# STM32U345xx register map
File version: 1.0
Registers are 32-bit, read-write, reset 0x0 unless marked. A register's access mark holds for its fields unless they carry their own. Offsets are from the block's base; [hi:lo] are bit positions; {n}, {i} and the like mark numbered series; 'fields as' and 'values as' point back to an identical list.

## TAMP — Tamper and backup registers
Base 0x40007C00
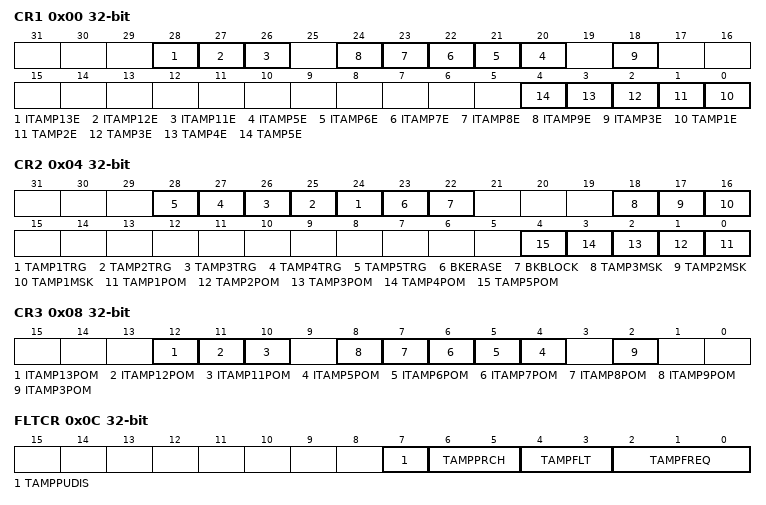
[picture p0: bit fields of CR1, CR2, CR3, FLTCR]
0x00 CR1 — TAMP configuration register 1
  [28] ITAMP13E, [27] ITAMP12E, [26] ITAMP11E, [n+15] ITAMP{n}E (n=5..9), [18] ITAMP3E, [n-1] TAMP{n}E (n=1..5)
0x04 CR2 — TAMP configuration register 2
  [n+23] TAMP{n}TRG (n=1..5), [23] BKERASE, [22] BKBLOCK, [18] TAMP3MSK, [17] TAMP2MSK, [16] TAMP1MSK, [n-1] TAMP{n}POM (n=1..5)
0x08 CR3 — TAMP configuration register 3
  [12] ITAMP13POM, [11] ITAMP12POM, [10] ITAMP11POM, [n-1] ITAMP{n}POM (n=5..9), [2] ITAMP3POM
0x0C FLTCR — TAMP filter control register
  [7] TAMPPUDIS
  [6:5] TAMPPRCH
    0=DURATION_1RTCCLK (Tamper pins are pre-charged before sampling during 1 RTCCLK cycle); 1=DURATION_2RTCCLK (Tamper pins are pre-charged before sampling during 2 RTCCLK cycles); 2=DURATION_4RTCCLK (Tamper pins are pre-charged before sampling during 4 RTCCLK cycles); 3=DURATION_8RTCCLK (Tamper pins are pre-charged before sampling during 8 RTCCLK cycles)
  [4:3] TAMPFLT
    0=DISABLE (Tamper filter is disabled); 1=FILTER_2SAMPLE (Tamper is activated after 2 consecutive samples at the active level); 2=FILTER_4SAMPLE (Tamper is activated after 4 consecutive samples at the active level); 3=FILTER_8SAMPLE (Tamper is activated after 8 consecutive samples at the active level)
  [2:0] TAMPFREQ
    0=SAMPLFREQDIV_32768 (Each of the tamper inputs are sampled with a frequency = RTCCLK / 32768); 1=SAMPLFREQDIV_16384 (Each of the tamper inputs are sampled with a frequency = RTCCLK / 16384); 2=SAMPLFREQDIV_8192 (Each of the tamper inputs are sampled with a frequency = RTCCLK / 8192); 3=SAMPLFREQDIV_4096 (Each of the tamper inputs are sampled with a frequency = RTCCLK / 4096); 4=SAMPLFREQDIV_2048 (Each of the tamper inputs are sampled with a frequency = RTCCLK / 2048); 5=SAMPLFREQDIV_1024 (Each of the tamper inputs are sampled with a frequency = RTCCLK / 1024); 6=SAMPLFREQDIV_512 (Each of the tamper inputs are sampled with a frequency = RTCCLK / 512); 7=SAMPLFREQDIV_256 (Each of the tamper inputs are sampled with a frequency = RTCCLK / 256)
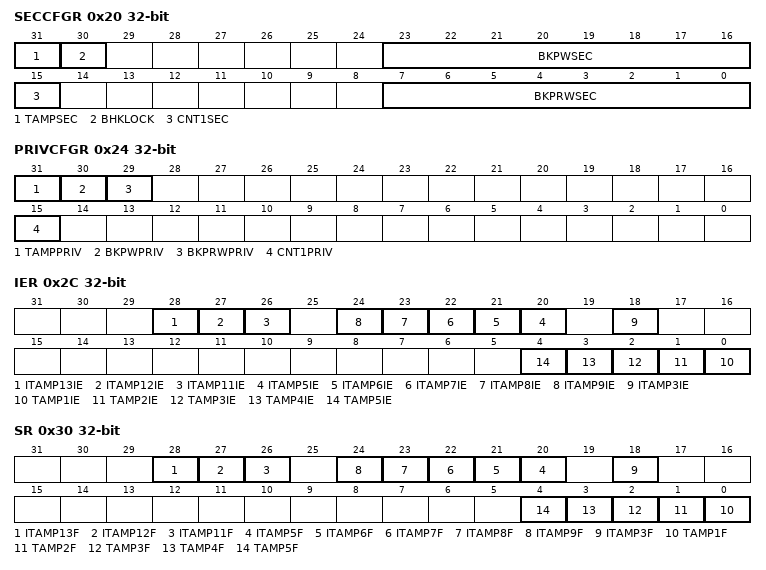
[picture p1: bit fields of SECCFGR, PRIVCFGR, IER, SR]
0x20 SECCFGR — TAMP secure mode control register
  [31] TAMPSEC
    1=YES (TAMP full secure); 0=NO (TAMP is not secure)
  [30] BHKLOCK
  [23:16] BKPWSEC
  [15] CNT1SEC
  [7:0] BKPRWSEC
0x24 PRIVCFGR — TAMP privilege mode control register
  [31] TAMPPRIV
    1=YES (TAMP full privilege); 0=NO (TAMP is not privilege)
  [30] BKPWPRIV
  [29] BKPRWPRIV
  [15] CNT1PRIV
0x2C IER — TAMP interrupt enable register
  [28] ITAMP13IE, [27] ITAMP12IE, [26] ITAMP11IE, [n+15] ITAMP{n}IE (n=5..9), [18] ITAMP3IE, [n-1] TAMP{n}IE (n=1..5)
0x30 SR — TAMP status register
  [28] ITAMP13F, [27] ITAMP12F, [26] ITAMP11F, [n+15] ITAMP{n}F (n=5..9), [18] ITAMP3F, [n-1] TAMP{n}F (n=1..5)
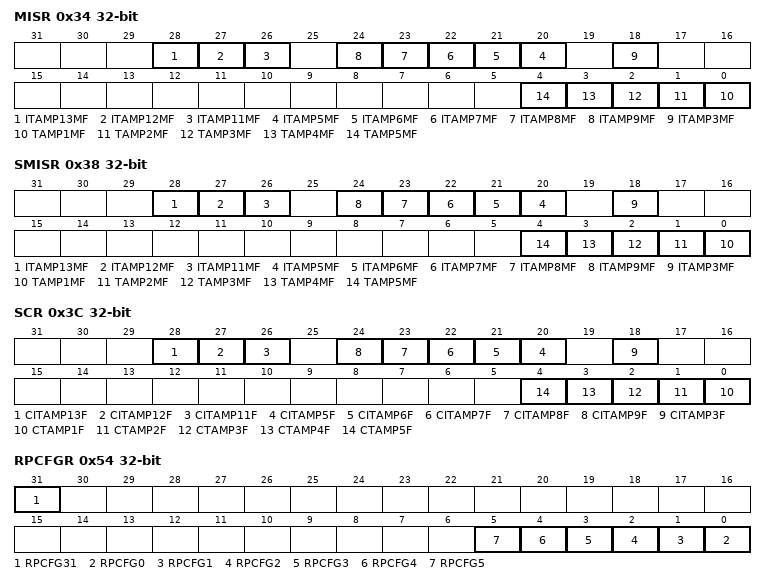
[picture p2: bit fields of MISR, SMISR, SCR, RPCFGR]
0x34 MISR — TAMP masked interrupt status register
  [28] ITAMP13MF, [27] ITAMP12MF, [26] ITAMP11MF, [n+15] ITAMP{n}MF (n=5..9), [18] ITAMP3MF, [n-1] TAMP{n}MF (n=1..5)
0x38 SMISR — TAMP secure masked interrupt status register
  fields as MISR
0x3C SCR — TAMP status clear register
  [28] CITAMP13F, [27] CITAMP12F, [26] CITAMP11F, [n+15] CITAMP{n}F (n=5..9), [18] CITAMP3F, [n-1] CTAMP{n}F (n=1..5)
0x40 COUNT1R — TAMP monotonic counter register
  [31:0] COUNT
0x54 RPCFGR — TAMP resources protection configuration register
  [31] RPCFG31, [n] RPCFG{n} (n=0..5)
{0x100+4i} BKP{i}R (i=0..31) — TAMP backup register {i}

## FDCAN_CONFIG — FD Controller Area Network Configuration
Base 0x4000A500
0x00 CKDIV — FDCAN clock divider register
  [3:0] PDIV — Input Clock Divider
0x204 OPTR — FDCAN option register
0x2F0 HWCFG — FDCAN hardware configuration register
0x2F4 VERR — FDCAN IP version register
0x2F8 IPIDR — FDCAN IP ID register
0x2FC SIDR — FDCAN size ID register

## USB_DRD_FS — Universal Serial Bus Full Speed Dual Role Device
Base 0x40016000
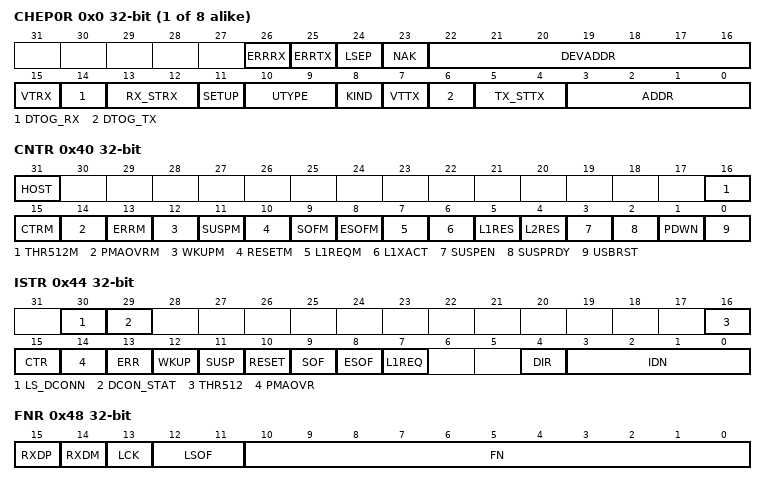
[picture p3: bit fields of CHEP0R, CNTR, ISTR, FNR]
{0x0+4i} CHEP{i}R (i=0..7) — USB Channel/Endpoint {i} register
  [26] ERRRX — Receive error
  [25] ERRTX — Transmit error
  [24] LSEP — Low Speed Endpoint (host with Hub Only)
  [23] NAK — Previous NAK detected
  [22:16] DEVADDR
  [15] VTRX — USB valid transaction received Mask
  [14] DTOG_RX — Data Toggle, for reception transfers Mask
  [13:12] RX_STRX — Status bits, for reception transfers Mask
  [11] SETUP — Setup transaction completed Mask
  [10:9] UTYPE — USB type of transaction Mask
  [8] KIND — EndPoint KIND Mask
  [7] VTTX — Valid USB transaction transmitted Mask
  [6] DTOG_TX — Data Toggle, for transmission transfers Mask
  [5:4] TX_STTX — Status bits, for transmission transfers Mask
  [3:0] ADDR — Endpoint address Mask
0x40 CNTR — Control register
  [31] HOST — Host Mode
  [16] THR512M — 512byte Threshold interrupt mask
  [15] CTRM — Correct Transfer Mask
  [14] PMAOVRM — DMA OVeR/underrun Mask
  [13] ERRM — ERRor Mask
  [12] WKUPM — WaKe UP Mask
  [11] SUSPM — SUSPend Mask
  [10] RESETM — RESET Mask
  [9] SOFM — Start Of Frame Mask
  [8] ESOFM — Expected Start Of Frame Mask
  [7] L1REQM — LPM L1 state request interrupt Mask
  [6] L1XACT — Host LPM L1 transaction request Mask
  [5] L1RES — LPM L1 Resume request/ Remote Wakeup Mask
  [4] L2RES — L2 Remote Wakeup / Resume driver Mask
  [3] SUSPEN — Suspend state enable Mask
  [2] SUSPRDY — Suspend state effective Mask
  [1] PDWN — Power DoWN Mask
  [0] USBRST — USB Reset Mask
0x44 ISTR — Interrupt status register
  [30] LS_DCONN — LS_DCONN Mask
  [29] DCON_STAT — Device Connection status (connected/Disconnected) don't cause an interrupt
  [16] THR512 — 512byte threshold interrupt (used with isochrnous single buffer )
  [15] CTR — Correct TRansfer (clear-only bit) Mask
  [14] PMAOVR — PMA OVeR/underrun (clear-only bit) Mask
  [13] ERR — ERRor (clear-only bit) Mask
  [12] WKUP — WaKe UP (clear-only bit) Mask
  [11] SUSP — SUSPend (clear-only bit) Mask
  [10] RESET — RESET Mask
  [9] SOF — Start Of Frame (clear-only bit) Mask
  [8] ESOF — Expected Start Of Frame (clear-only bit) Mask
  [7] L1REQ — LPM L1 state request Mask
  [4] DIR — DIRection of transaction (read-only bit) Mask
  [3:0] IDN — EndPoint IDentifier (read-only bit) Mask
0x48 FNR — Frame number register
  [15] RXDP — status of D+ data line Mask
  [14] RXDM — status of D- data line Mask
  [13] LCK — LoCKed Mask
  [12:11] LSOF — Lost SOF Mask
  [10:0] FN — Frame Number Mask
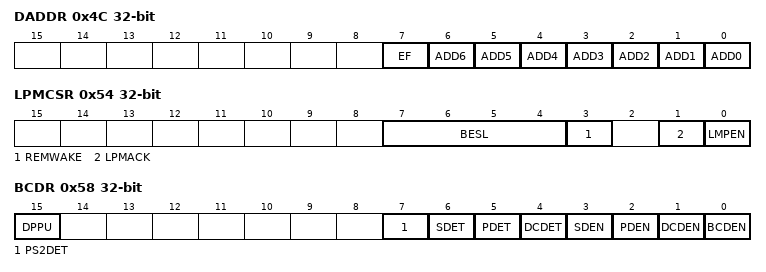
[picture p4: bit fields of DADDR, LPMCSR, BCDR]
0x4C DADDR — Device address register
  [7] EF — Enable Function Mask
  [n] ADD{n} (n=0..6) — Bit {n} Mask
0x54 LPMCSR — LPM Control and Status register
  [7:4] BESL — BESL value received with last ACKed LPM Token Mask
  [3] REMWAKE — bRemoteWake value received with last ACKed LPM Token Mask
  [1] LPMACK — LPM Token acknowledge enable Mask
  [0] LMPEN — LPM support enable Mask
0x58 BCDR — Battery Charging detector register
  [15] DPPU — DP Pull-up Enable Mask
  [7] PS2DET — PS2 port or proprietary charger detected Mask
  [6] SDET — Secondary detection (SD) status Mask
  [5] PDET — Primary detection (PD) status Mask
  [4] DCDET — Data contact detection (DCD) status Mask
  [3] SDEN — Secondary detection (SD) mode enable Mask
  [2] PDEN — Primary detection (PD) mode enable Mask
  [1] DCDEN — Data contact detection (DCD) mode enable Mask
  [0] BCDEN — Battery charging detector (BCD) enable Mask
